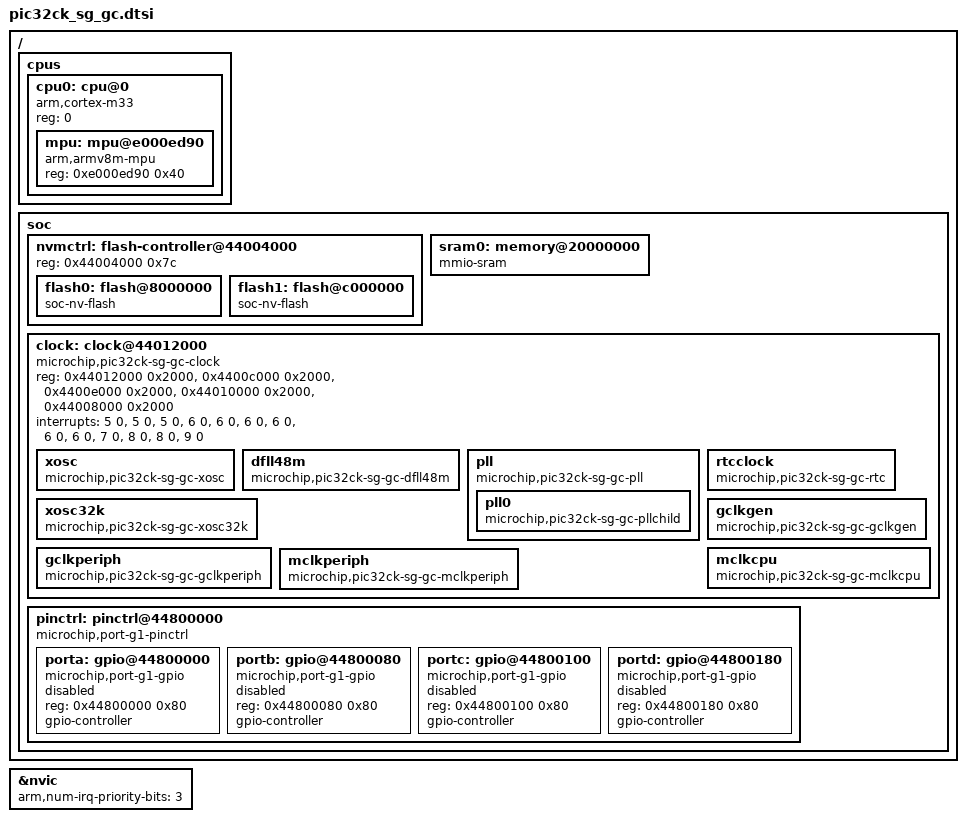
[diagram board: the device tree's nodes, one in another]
/*
 * Copyright (c) 2026 Microchip Technology Inc.
 *
 * SPDX-License-Identifier: Apache-2.0
 */

#include <arm/armv8-m.dtsi>
#include <zephyr/dt-bindings/gpio/gpio.h>
#include <zephyr/dt-bindings/clock/mchp_pic32ck_sg_gc_clock.h>

/ {
	cpus {
		#address-cells = <1>;
		#size-cells = <0>;

		cpu0: cpu@0 {
			device_type = "cpu";
			compatible = "arm,cortex-m33";
			reg = <0>;
			#address-cells = <1>;
			#size-cells = <1>;

			mpu: mpu@e000ed90 {
				compatible = "arm,armv8m-mpu";
				reg = <0xe000ed90 0x40>; /* 64 bytes for ARMv8-M MPU */
			};
		};
	};

	soc {
		nvmctrl: flash-controller@44004000 {
			reg = <0x44004000 0x7c>;
			#address-cells = <1>;
			#size-cells = <1>;
			ranges;

			flash0: flash@8000000 {
				compatible = "soc-nv-flash";
				#address-cells = <1>;
				#size-cells = <1>;
			};

			flash1: flash@c000000 {
				compatible = "soc-nv-flash";
				#address-cells = <1>;
				#size-cells = <1>;
			};
		};

		sram0: memory@20000000 {
			compatible = "mmio-sram";
		};

		clock: clock@44012000 {
			compatible = "microchip,pic32ck-sg-gc-clock";
			reg = <0x44012000 0x2000>, <0x4400c000 0x2000>, <0x4400e000 0x2000>,
			      <0x44010000 0x2000>, <0x44008000 0x2000>;
			reg-names = "mclk", "oscctrl", "osc32kctrl", "gclk", "supc";
			interrupts = <5 0>, <5 0>, <5 0>, <6 0>, <6 0>,
				     <6 0>, <6 0>, <6 0>, <6 0>,
				     <7 0>, <8 0>, <8 0>, <9 0>;
			interrupt-names = "xosc-fail", "xosc-crdy", "clk-fail", "dfll-rdy",
					  "dfll-lock", "dfll-ovf", "dfll-unf", "dfll-rcs",
					  "dfll-fail", "pll0-ckr", "xosc32k-rdy", "xosc32k-fail",
					  "ckrdy";

			xosc: xosc {
				compatible = "microchip,pic32ck-sg-gc-xosc";
			};

			dfll48m: dfll48m {
				compatible = "microchip,pic32ck-sg-gc-dfll48m";
			};

			pll: pll {
				compatible = "microchip,pic32ck-sg-gc-pll";

				pll0: pll0 {
					compatible = "microchip,pic32ck-sg-gc-pllchild";
				};
			};

			rtcclock: rtcclock {
				compatible = "microchip,pic32ck-sg-gc-rtc";
				#clock-cells = <1>;
			};

			xosc32k: xosc32k {
				compatible = "microchip,pic32ck-sg-gc-xosc32k";
			};

			gclkgen: gclkgen {
				compatible = "microchip,pic32ck-sg-gc-gclkgen";
			};

			gclkperiph: gclkperiph {
				compatible = "microchip,pic32ck-sg-gc-gclkperiph";
				#clock-cells = <1>;
			};

			mclkcpu: mclkcpu {
				compatible = "microchip,pic32ck-sg-gc-mclkcpu";
			};

			mclkperiph: mclkperiph {
				compatible = "microchip,pic32ck-sg-gc-mclkperiph";
				#clock-cells = <1>;
			};
		};

		pinctrl: pinctrl@44800000 {
			compatible = "microchip,port-g1-pinctrl";
			#address-cells = <1>;
			#size-cells = <1>;
			ranges = <0x44800000 0x44800000 0x200>;

			porta: gpio@44800000 {
				compatible = "microchip,port-g1-gpio";
				reg = <0x44800000 0x80>;
				gpio-controller;
				#gpio-cells = <2>;
				#microchip,pin-cells = <2>;
				status = "disabled";
			};

			portb: gpio@44800080 {
				compatible = "microchip,port-g1-gpio";
				reg = <0x44800080 0x80>;
				gpio-controller;
				#gpio-cells = <2>;
				#microchip,pin-cells = <2>;
				status = "disabled";
			};

			portc: gpio@44800100 {
				compatible = "microchip,port-g1-gpio";
				reg = <0x44800100 0x80>;
				gpio-controller;
				#gpio-cells = <2>;
				#microchip,pin-cells = <2>;
				status = "disabled";
			};

			portd: gpio@44800180 {
				compatible = "microchip,port-g1-gpio";
				reg = <0x44800180 0x80>;
				gpio-controller;
				#gpio-cells = <2>;
				#microchip,pin-cells = <2>;
				status = "disabled";
			};
		};
	};
};

&nvic {
	arm,num-irq-priority-bits = <3>;
};
